VERSION ""

NS_ :

BS_:

BU_: DBG DRIVER IO MOTOR SENSOR

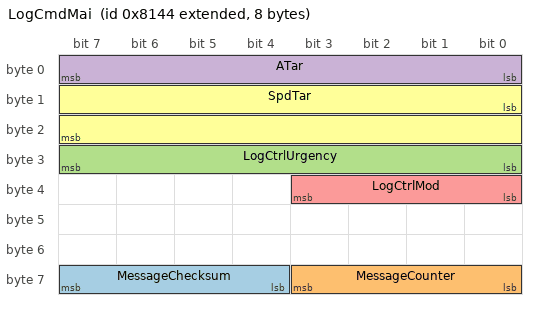
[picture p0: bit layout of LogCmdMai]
BO_ 2147516740 LogCmdMai: 8 Bywire_Tx
 SG_ MessageChecksum : 60|4@1+ (1,0) [0|15] "" Vector__XXX
 SG_ MessageCounter : 56|4@1+ (1,0) [0|15] "" Vector__XXX
 SG_ LogCtrlUrgency : 24|8@1+ (0.4,0) [0|102] "%" Vector__XXX
 SG_ ATar : 0|8@1+ (0.1,-12.5) [-12.5|13] "" Vector__XXX
 SG_ LogCtrlMod : 32|4@1+ (1,0) [0|15] "" Vector__XXX
 SG_ SpdTar : 8|16@1+ (0.00390625,0) [0|250.996] "km/h" Vector__XXX

CM_ BU_ DRIVER "The driver controller driving the car";
CM_ BU_ MOTOR "The motor controller of the car";
CM_ BU_ SENSOR "The sensor controller of the car";
CM_ BO_ 100 "Sync message used to synchronize the controllers";

BA_DEF_ "BusType" STRING ;
BA_DEF_ BO_ "GenMsgCycleTime" INT 0 0;
BA_DEF_ SG_ "FieldType" STRING ;

BA_DEF_DEF_ "BusType" "CAN";
BA_DEF_DEF_ "FieldType" "";
BA_DEF_DEF_ "GenMsgCycleTime" 0;

BA_ "GenMsgCycleTime" BO_ 100 1000;
BA_ "GenMsgCycleTime" BO_ 500 100;
BA_ "GenMsgCycleTime" BO_ 101 100;
BA_ "GenMsgCycleTime" BO_ 400 100;
BA_ "GenMsgCycleTime" BO_ 200 100;
BA_ "FieldType" SG_ 100 DRIVER_HEARTBEAT_cmd "DRIVER_HEARTBEAT_cmd";
BA_ "FieldType" SG_ 500 IO_DEBUG_test_enum "IO_DEBUG_test_enum";

VAL_ 100 DRIVER_HEARTBEAT_cmd 2 "DRIVER_HEARTBEAT_cmd_REBOOT" 1 "DRIVER_HEARTBEAT_cmd_SYNC" 0 "DRIVER_HEARTBEAT_cmd_NOOP" ;
VAL_ 500 IO_DEBUG_test_enum 2 "IO_DEBUG_test2_enum_two" 1 "IO_DEBUG_test2_enum_one" ;
